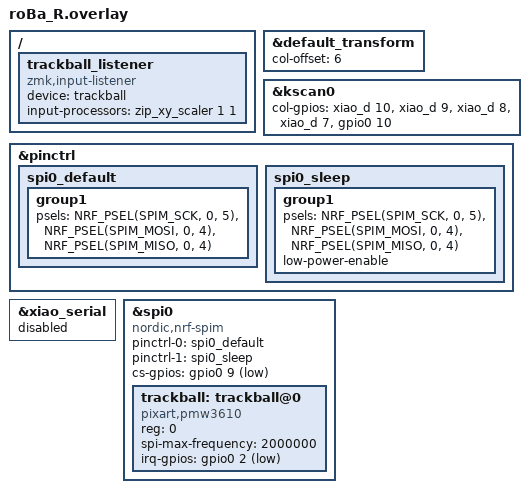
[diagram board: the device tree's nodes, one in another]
#include "roBa.dtsi"
#include <input/processors.dtsi>

/* スクロール用の設定が残っている可能性を排除するため、一旦ここでXY移動を明示 */
/ {
    trackball_listener: trackball_listener {
        compatible = "zmk,input-listener";
        device = <&trackball>;
        status = "okay";

        /* トラックボールの生の動きを、通常のマウス移動（XY）として処理させる記述 */
        input-processors = <&zip_xy_scaler 1 1>; 
    };
};

&default_transform {
    col-offset = <6>;
};

&kscan0 {
        col-gpios
            = <&xiao_d 10 GPIO_ACTIVE_HIGH>
            , <&xiao_d 9 GPIO_ACTIVE_HIGH>
            , <&xiao_d 8 GPIO_ACTIVE_HIGH>
            , <&xiao_d 7 GPIO_ACTIVE_HIGH>
            , <&gpio0 10 GPIO_ACTIVE_HIGH>
            ;
};

&pinctrl {
    spi0_default: spi0_default {
        group1 {
            psels = <NRF_PSEL(SPIM_SCK, 0, 5)>,
                <NRF_PSEL(SPIM_MOSI, 0, 4)>,
                <NRF_PSEL(SPIM_MISO, 0, 4)>;
        };
    };

    spi0_sleep: spi0_sleep {
        group1 {
            psels = <NRF_PSEL(SPIM_SCK, 0, 5)>,
                <NRF_PSEL(SPIM_MOSI, 0, 4)>,
                <NRF_PSEL(SPIM_MISO, 0, 4)>;
            low-power-enable;
        };
    };
};

&xiao_serial { status = "disabled"; };

&spi0 {
    status = "okay";
    compatible = "nordic,nrf-spim";
    pinctrl-0 = <&spi0_default>;
    pinctrl-1 = <&spi0_sleep>;
    pinctrl-names = "default", "sleep";
    cs-gpios = <&gpio0 9 GPIO_ACTIVE_LOW>;

    trackball: trackball@0 {
        status = "okay";
        compatible = "pixart,pmw3610";
        reg = <0>;
        spi-max-frequency = <2000000>;
        irq-gpios = <&gpio0 2 (GPIO_ACTIVE_LOW | GPIO_PULL_UP)>;
        
        /* 自動切り替えは一旦コメントアウトのままでOKです。
           これで動くようになった後、特定のレイヤー（マウスボタンがあるレイヤーなど）に
           自動で飛ばしたい場合は、ここのコメントアウトを解除して番号を指定します。
        */
        // automouse-layer = <4>;
    };
};
